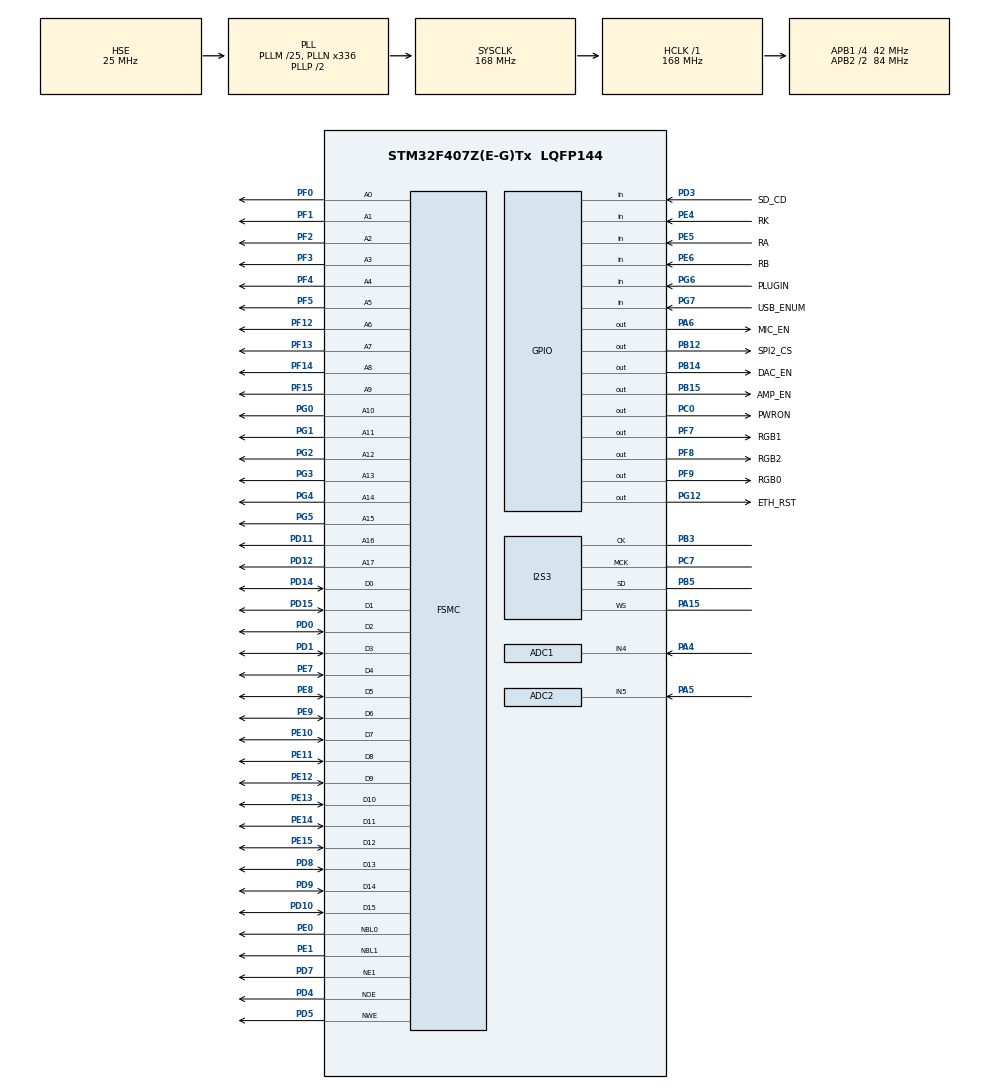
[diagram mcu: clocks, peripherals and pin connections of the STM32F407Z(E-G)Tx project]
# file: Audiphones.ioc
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ADC1.Channel-0\#ChannelRegularConversion=ADC_CHANNEL_4
ADC1.ClockPrescaler=ADC_CLOCK_SYNC_PCLK_DIV8
ADC1.ContinuousConvMode=DISABLE
ADC1.DMAContinuousRequests=DISABLE
ADC1.DataAlign=ADC_DATAALIGN_LEFT
ADC1.DiscontinuousConvMode=DISABLE
ADC1.EOCSelection=ADC_EOC_SINGLE_CONV
ADC1.EnableAnalogWatchDog=false
ADC1.ExternalTrigConv=ADC_SOFTWARE_START
ADC1.ExternalTrigConvEdge=ADC_EXTERNALTRIGCONVEDGE_NONE
ADC1.InjNumberOfConversion=0
ADC1.NbrOfConversion=1
ADC1.NbrOfConversionFlag=1
ADC1.Rank-0\#ChannelRegularConversion=1
ADC1.Resolution=ADC_RESOLUTION_12B
ADC1.SamplingTime-0\#ChannelRegularConversion=ADC_SAMPLETIME_3CYCLES
ADC1.ScanConvMode=DISABLE
ADC1.master=1
ADC2.Channel-0\#ChannelRegularConversion=ADC_CHANNEL_5
ADC2.ClockPrescaler=ADC_CLOCK_SYNC_PCLK_DIV8
ADC2.NbrOfConversionFlag=1
ADC2.Rank-0\#ChannelRegularConversion=1
ADC2.SamplingTime-0\#ChannelRegularConversion=ADC_SAMPLETIME_3CYCLES
FSMC.AddressSetupTime1=6
FSMC.BusTurnAroundDuration1=6
FSMC.DataSetupTime1=9
FSMC.WriteOperation1=FSMC_WRITE_OPERATION_ENABLE
I2S3.AudioFreq=I2S_AUDIOFREQ_16K
I2S3.ErrorAudioFreq=1.9 %
I2S3.FullDuplexMode=I2S_FULLDUPLEXMODE_DISABLE
I2S3.Instance=SPI$Index
I2S3.RealAudioFreq=16.304 KHz
I2S3.VirtualMode=I2S_MODE_MASTER
Mcu.Family=STM32F4
Mcu.Name=STM32F407Z(E-G)Tx
Mcu.Package=LQFP144
NVIC.PriorityGroup=NVIC_PRIORITYGROUP_2
NVIC.TIM3_IRQn=true\:0\:0\:false\:false\:true\:true
PA0-WKUP.Mode=SYS_WakeUp0
PA0-WKUP.Signal=SYS_WKUP
PA13.Mode=Serial_Wire
PA13.Signal=SYS_JTMS-SWDIO
PA14.Mode=Serial_Wire
PA14.Signal=SYS_JTCK-SWCLK
PA15.Mode=Half_Duplex_Master
PA15.Signal=I2S3_WS
PA4.Signal=ADCx_IN4
PA5.Signal=ADCx_IN5
PA6.GPIO_Label=MIC_EN
PA6.Signal=GPIO_Output
PB12.GPIO_Label=SPI2_CS
PB12.PinState=GPIO_PIN_SET
PB12.Signal=GPIO_Output
PB14.GPIO_Label=DAC_EN
PB14.Signal=GPIO_Output
PB15.GPIO_Label=AMP_EN
PB15.Signal=GPIO_Output
PB3.Mode=Half_Duplex_Master
PB3.Signal=I2S3_CK
PB5.Mode=Half_Duplex_Master
PB5.Signal=I2S3_SD
PC0.GPIO_Label=PWRON
PC0.Signal=GPIO_Output
PC14-OSC32_IN.Mode=LSE-External-Oscillator
PC14-OSC32_IN.Signal=RCC_OSC32_IN
PC15-OSC32_OUT.Mode=LSE-External-Oscillator
PC15-OSC32_OUT.Signal=RCC_OSC32_OUT
PC7.Mode=Master_Clock_Activated
PC7.Signal=I2S3_MCK
PD0.Signal=FSMC_D2_DA2
PD1.Signal=FSMC_D3_DA3
PD10.Signal=FSMC_D15_DA15
PD11.Signal=FSMC_A16_CLE
PD12.Signal=FSMC_A17_ALE
PD14.Signal=FSMC_D0_DA0
PD15.Signal=FSMC_D1_DA1
PD3.GPIO_Label=SD_CD
PD3.Signal=GPIO_Input
PD4.Signal=FSMC_NOE
PD5.Signal=FSMC_NWE
PD7.Mode=NorPsramChipSelect1_1
PD7.Signal=FSMC_NE1
PD8.Signal=FSMC_D13_DA13
PD9.Signal=FSMC_D14_DA14
PE0.Signal=FSMC_NBL0
PE1.Signal=FSMC_NBL1
PE10.Signal=FSMC_D7_DA7
PE11.Signal=FSMC_D8_DA8
PE12.Signal=FSMC_D9_DA9
PE13.Signal=FSMC_D10_DA10
PE14.Signal=FSMC_D11_DA11
PE15.Signal=FSMC_D12_DA12
PE4.GPIO_Label=RK
PE4.Signal=GPIO_Input
PE5.GPIO_Label=RA
PE5.Signal=GPIO_Input
PE6.GPIO_Label=RB
PE6.Signal=GPIO_Input
PE7.Signal=FSMC_D4_DA4
PE8.Signal=FSMC_D5_DA5
PE9.Signal=FSMC_D6_DA6
PF0.Signal=FSMC_A0
PF1.Signal=FSMC_A1
PF12.Signal=FSMC_A6
PF13.Signal=FSMC_A7
PF14.Signal=FSMC_A8
PF15.Signal=FSMC_A9
PF2.Signal=FSMC_A2
PF3.Signal=FSMC_A3
PF4.Signal=FSMC_A4
PF5.Signal=FSMC_A5
PF7.GPIO_Label=RGB1
PF7.Signal=GPIO_Output
PF8.GPIO_Label=RGB2
PF8.Signal=GPIO_Output
PF9.GPIO_Label=RGB0
PF9.Signal=GPIO_Output
PG0.Signal=FSMC_A10
PG1.Signal=FSMC_A11
PG12.GPIO_Label=ETH_RST
PG12.PinState=GPIO_PIN_SET
PG12.Signal=GPIO_Output
PG2.Signal=FSMC_A12
PG3.Signal=FSMC_A13
PG4.Signal=FSMC_A14
PG5.Signal=FSMC_A15
PG6.GPIO_Label=PLUGIN
PG6.Signal=GPIO_Input
PG7.GPIO_Label=USB_ENUM
PG7.Signal=GPIO_Input
PH0-OSC_IN.Mode=HSE-External-Oscillator
PH0-OSC_IN.Signal=RCC_OSC_IN
PH1-OSC_OUT.Mode=HSE-External-Oscillator
PH1-OSC_OUT.Signal=RCC_OSC_OUT
ProjectManager.HeapSize=0x800
ProjectManager.StackSize=0x400
ProjectManager.TargetToolchain=MDK-ARM V5
RCC.48MHZClocksFreq_Value=48000000
RCC.AHBFreq_Value=168000000
RCC.APB1CLKDivider=RCC_HCLK_DIV4
RCC.APB1Freq_Value=42000000
RCC.APB1TimFreq_Value=84000000
RCC.APB2CLKDivider=RCC_HCLK_DIV2
RCC.APB2Freq_Value=84000000
RCC.APB2TimFreq_Value=168000000
RCC.CortexFreq_Value=21000000
RCC.Cortex_Div=SYSTICK_CLKSOURCE_HCLK_DIV8
RCC.EnbaleCSS=true
RCC.HCLKFreq_Value=168000000
RCC.HSE_VALUE=25000000
RCC.HSI_VALUE=16000000
RCC.PLLM=25
RCC.PLLN=336
RCC.PLLQ=7
RCC.PLLSourceVirtual=RCC_PLLSOURCE_HSE
RCC.RCC_RTC_Clock_SourceVirtual=RCC_RTCCLKSOURCE_LSE
RCC.SYSCLKFreq_VALUE=168000000
RCC.SYSCLKSource=RCC_SYSCLKSOURCE_PLLCLK
RCC.VCOOutputFreq_Value=336000000
SH.ADCx_IN4.0=ADC1_IN4,IN4
SH.ADCx_IN5.0=ADC2_IN5,IN5
SH.FSMC_A0.0=FSMC_A0,18b-a1
SH.FSMC_A1.0=FSMC_A1,18b-a1
SH.FSMC_A10.0=FSMC_A10,18b-a1
SH.FSMC_A11.0=FSMC_A11,18b-a1
SH.FSMC_A12.0=FSMC_A12,18b-a1
SH.FSMC_A13.0=FSMC_A13,18b-a1
SH.FSMC_A14.0=FSMC_A14,18b-a1
SH.FSMC_A15.0=FSMC_A15,18b-a1
SH.FSMC_A16_CLE.0=FSMC_A16,18b-a1
SH.FSMC_A17_ALE.0=FSMC_A17,18b-a1
SH.FSMC_A2.0=FSMC_A2,18b-a1
SH.FSMC_A3.0=FSMC_A3,18b-a1
SH.FSMC_A4.0=FSMC_A4,18b-a1
SH.FSMC_A5.0=FSMC_A5,18b-a1
SH.FSMC_A6.0=FSMC_A6,18b-a1
SH.FSMC_A7.0=FSMC_A7,18b-a1
SH.FSMC_A8.0=FSMC_A8,18b-a1
SH.FSMC_A9.0=FSMC_A9,18b-a1
SH.FSMC_D0_DA0.0=FSMC_D0,16b-d1
SH.FSMC_D10_DA10.0=FSMC_D10,16b-d1
SH.FSMC_D11_DA11.0=FSMC_D11,16b-d1
SH.FSMC_D12_DA12.0=FSMC_D12,16b-d1
SH.FSMC_D13_DA13.0=FSMC_D13,16b-d1
SH.FSMC_D14_DA14.0=FSMC_D14,16b-d1
SH.FSMC_D15_DA15.0=FSMC_D15,16b-d1
SH.FSMC_D1_DA1.0=FSMC_D1,16b-d1
SH.FSMC_D2_DA2.0=FSMC_D2,16b-d1
SH.FSMC_D3_DA3.0=FSMC_D3,16b-d1
SH.FSMC_D4_DA4.0=FSMC_D4,16b-d1
SH.FSMC_D5_DA5.0=FSMC_D5,16b-d1
SH.FSMC_D6_DA6.0=FSMC_D6,16b-d1
SH.FSMC_D7_DA7.0=FSMC_D7,16b-d1
SH.FSMC_D8_DA8.0=FSMC_D8,16b-d1
SH.FSMC_D9_DA9.0=FSMC_D9,16b-d1
SH.FSMC_NBL0.0=FSMC_NBL0,2ByteEnable1
SH.FSMC_NBL1.0=FSMC_NBL1,2ByteEnable1
SH.FSMC_NOE.0=FSMC_NOE,Sram1
SH.FSMC_NWE.0=FSMC_NWE,Sram1
TIM3.ClockDivision=TIM_CLOCKDIVISION_DIV2
TIM3.Period=2625-1
VP_TIM3_VS_ClockSourceINT.Mode=Internal
board=Audiphones

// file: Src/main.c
/**
  ******************************************************************************
  * File Name          : main.c
  * Description        : Main program body
  ******************************************************************************
  ** This notice applies to any and all portions of this file
  * that are not between comment pairs USER CODE BEGIN and
  * USER CODE END. Other portions of this file, whether
  * inserted by the user or by software development tools
  * are owned by their respective copyright owners.
  *
  * COPYRIGHT(c) 2017 STMicroelectronics
  *
  * Redistribution and use in source and binary forms, with or without modification,
  * are permitted provided that the following conditions are met:
  *   1. Redistributions of source code must retain the above copyright notice,
  *      this list of conditions and the following disclaimer.
  *   2. Redistributions in binary form must reproduce the above copyright notice,
  *      this list of conditions and the following disclaimer in the documentation
  *      and/or other materials provided with the distribution.
  *   3. Neither the name of STMicroelectronics nor the names of its contributors
  *      may be used to endorse or promote products derived from this software
  *      without specific prior written permission.
  *
  * THIS SOFTWARE IS PROVIDED BY THE COPYRIGHT HOLDERS AND CONTRIBUTORS "AS IS"
  * AND ANY EXPRESS OR IMPLIED WARRANTIES, INCLUDING, BUT NOT LIMITED TO, THE
  * IMPLIED WARRANTIES OF MERCHANTABILITY AND FITNESS FOR A PARTICULAR PURPOSE ARE
  * DISCLAIMED. IN NO EVENT SHALL THE COPYRIGHT HOLDER OR CONTRIBUTORS BE LIABLE
  * FOR ANY DIRECT, INDIRECT, INCIDENTAL, SPECIAL, EXEMPLARY, OR CONSEQUENTIAL
  * DAMAGES (INCLUDING, BUT NOT LIMITED TO, PROCUREMENT OF SUBSTITUTE GOODS OR
  * SERVICES; LOSS OF USE, DATA, OR PROFITS; OR BUSINESS INTERRUPTION) HOWEVER
  * CAUSED AND ON ANY THEORY OF LIABILITY, WHETHER IN CONTRACT, STRICT LIABILITY,
  * OR TORT (INCLUDING NEGLIGENCE OR OTHERWISE) ARISING IN ANY WAY OUT OF THE USE
  * OF THIS SOFTWARE, EVEN IF ADVISED OF THE POSSIBILITY OF SUCH DAMAGE.
  *
  ******************************************************************************
  */
#include "main.h"
#include "stm32f4xx_hal.h"

ADC_HandleTypeDef hadc1;
ADC_HandleTypeDef hadc2;

I2S_HandleTypeDef hi2s3;

TIM_HandleTypeDef htim3;

SRAM_HandleTypeDef hsram1;

/* USER CODE BEGIN PV */
/* Private variables ---------------------------------------------------------*/

/* USER CODE END PV */

void SystemClock_Config(void);
static void MX_GPIO_Init(void);
static void MX_FSMC_Init(void);
static void MX_ADC1_Init(void);
static void MX_ADC2_Init(void);
static void MX_TIM3_Init(void);
static void MX_I2S3_Init(void);

/* USER CODE BEGIN PFP */
/* Private function prototypes -----------------------------------------------*/

/* USER CODE END PFP */

int main(void)
{

  /* MCU Configuration----------------------------------------------------------*/

  /* Reset of all peripherals, Initializes the Flash interface and the Systick. */
  HAL_Init();

  /* Configure the system clock */
  SystemClock_Config();

  /* Initialize all configured peripherals */
  MX_GPIO_Init();
  MX_FSMC_Init();
  MX_ADC1_Init();
  MX_ADC2_Init();
  MX_TIM3_Init();
  MX_I2S3_Init();

  /* Infinite loop */
  /* USER CODE BEGIN WHILE */
  HAL_GPIO_WritePin(DAC_EN_GPIO_Port,DAC_EN_Pin,GPIO_PIN_SET);
  HAL_GPIO_WritePin(AMP_EN_GPIO_Port,AMP_EN_Pin,GPIO_PIN_SET);
  HAL_GPIO_WritePin(MIC_EN_GPIO_Port,MIC_EN_Pin,GPIO_PIN_SET);
   HAL_TIM_Base_Start_IT(&htim3);
  while (1)
  {
  /* USER CODE END WHILE */

  }

}

/** System Clock Configuration
*/
void SystemClock_Config(void)
{

  RCC_OscInitTypeDef RCC_OscInitStruct;
  RCC_ClkInitTypeDef RCC_ClkInitStruct;
  RCC_PeriphCLKInitTypeDef PeriphClkInitStruct;

    /**Configure the main internal regulator output voltage
    */
  __HAL_RCC_PWR_CLK_ENABLE();

  __HAL_PWR_VOLTAGESCALING_CONFIG(PWR_REGULATOR_VOLTAGE_SCALE1);

    /**Initializes the CPU, AHB and APB busses clocks
    */
  RCC_OscInitStruct.OscillatorType = RCC_OSCILLATORTYPE_HSE;
  RCC_OscInitStruct.HSEState = RCC_HSE_ON;
  RCC_OscInitStruct.PLL.PLLState = RCC_PLL_ON;
  RCC_OscInitStruct.PLL.PLLSource = RCC_PLLSOURCE_HSE;
  RCC_OscInitStruct.PLL.PLLM = 25;
  RCC_OscInitStruct.PLL.PLLN = 336;
  RCC_OscInitStruct.PLL.PLLP = RCC_PLLP_DIV2;
  RCC_OscInitStruct.PLL.PLLQ = 7;
  if (HAL_RCC_OscConfig(&RCC_OscInitStruct) != HAL_OK)
  {
    _Error_Handler(__FILE__, __LINE__);
  }

    /**Initializes the CPU, AHB and APB busses clocks
    */
  RCC_ClkInitStruct.ClockType = RCC_CLOCKTYPE_HCLK|RCC_CLOCKTYPE_SYSCLK
                              |RCC_CLOCKTYPE_PCLK1|RCC_CLOCKTYPE_PCLK2;
  RCC_ClkInitStruct.SYSCLKSource = RCC_SYSCLKSOURCE_PLLCLK;
  RCC_ClkInitStruct.AHBCLKDivider = RCC_SYSCLK_DIV1;
  RCC_ClkInitStruct.APB1CLKDivider = RCC_HCLK_DIV4;
  RCC_ClkInitStruct.APB2CLKDivider = RCC_HCLK_DIV2;

  if (HAL_RCC_ClockConfig(&RCC_ClkInitStruct, FLASH_LATENCY_5) != HAL_OK)
  {
    _Error_Handler(__FILE__, __LINE__);
  }

  PeriphClkInitStruct.PeriphClockSelection = RCC_PERIPHCLK_I2S;
  PeriphClkInitStruct.PLLI2S.PLLI2SN = 192;
  PeriphClkInitStruct.PLLI2S.PLLI2SR = 2;
  if (HAL_RCCEx_PeriphCLKConfig(&PeriphClkInitStruct) != HAL_OK)
  {
    _Error_Handler(__FILE__, __LINE__);
  }

    /**Enables the Clock Security System
    */
  HAL_RCC_EnableCSS();

    /**Configure the Systick interrupt time
    */
  HAL_SYSTICK_Config(HAL_RCC_GetHCLKFreq()/8000);

    /**Configure the Systick
    */
  HAL_SYSTICK_CLKSourceConfig(SYSTICK_CLKSOURCE_HCLK_DIV8);

  /* SysTick_IRQn interrupt configuration */
  HAL_NVIC_SetPriority(SysTick_IRQn, 0, 0);
}

/* ADC1 init function */
static void MX_ADC1_Init(void)
{

  ADC_ChannelConfTypeDef sConfig;

    /**Configure the global features of the ADC (Clock, Resolution, Data Alignment and number of conversion)
    */
  hadc1.Instance = ADC1;
  hadc1.Init.ClockPrescaler = ADC_CLOCK_SYNC_PCLK_DIV8;
  hadc1.Init.Resolution = ADC_RESOLUTION_12B;
  hadc1.Init.ScanConvMode = DISABLE;
  hadc1.Init.ContinuousConvMode = DISABLE;
  hadc1.Init.DiscontinuousConvMode = DISABLE;
  hadc1.Init.ExternalTrigConvEdge = ADC_EXTERNALTRIGCONVEDGE_NONE;
  hadc1.Init.ExternalTrigConv = ADC_SOFTWARE_START;
  hadc1.Init.DataAlign = ADC_DATAALIGN_LEFT;
  hadc1.Init.NbrOfConversion = 1;
  hadc1.Init.DMAContinuousRequests = DISABLE;
  hadc1.Init.EOCSelection = ADC_EOC_SINGLE_CONV;
  if (HAL_ADC_Init(&hadc1) != HAL_OK)
  {
    _Error_Handler(__FILE__, __LINE__);
  }

    /**Configure for the selected ADC regular channel its corresponding rank in the sequencer and its sample time.
    */
  sConfig.Channel = ADC_CHANNEL_4;
  sConfig.Rank = 1;
  sConfig.SamplingTime = ADC_SAMPLETIME_3CYCLES;
  if (HAL_ADC_ConfigChannel(&hadc1, &sConfig) != HAL_OK)
  {
    _Error_Handler(__FILE__, __LINE__);
  }

}

/* ADC2 init function */
static void MX_ADC2_Init(void)
{

  ADC_ChannelConfTypeDef sConfig;

    /**Configure the global features of the ADC (Clock, Resolution, Data Alignment and number of conversion)
    */
  hadc2.Instance = ADC2;
  hadc2.Init.ClockPrescaler = ADC_CLOCK_SYNC_PCLK_DIV8;
  hadc2.Init.Resolution = ADC_RESOLUTION_12B;
  hadc2.Init.ScanConvMode = DISABLE;
  hadc2.Init.ContinuousConvMode = DISABLE;
  hadc2.Init.DiscontinuousConvMode = DISABLE;
  hadc2.Init.ExternalTrigConvEdge = ADC_EXTERNALTRIGCONVEDGE_NONE;
  hadc2.Init.ExternalTrigConv = ADC_SOFTWARE_START;
  hadc2.Init.DataAlign = ADC_DATAALIGN_RIGHT;
  hadc2.Init.NbrOfConversion = 1;
  hadc2.Init.DMAContinuousRequests = DISABLE;
  hadc2.Init.EOCSelection = ADC_EOC_SINGLE_CONV;
  if (HAL_ADC_Init(&hadc2) != HAL_OK)
  {
    _Error_Handler(__FILE__, __LINE__);
  }

    /**Configure for the selected ADC regular channel its corresponding rank in the sequencer and its sample time.
    */
  sConfig.Channel = ADC_CHANNEL_5;
  sConfig.Rank = 1;
  sConfig.SamplingTime = ADC_SAMPLETIME_3CYCLES;
  if (HAL_ADC_ConfigChannel(&hadc2, &sConfig) != HAL_OK)
  {
    _Error_Handler(__FILE__, __LINE__);
  }

}

/* I2S3 init function */
static void MX_I2S3_Init(void)
{

  hi2s3.Instance = SPI3;
  hi2s3.Init.Mode = I2S_MODE_MASTER_TX;
  hi2s3.Init.Standard = I2S_STANDARD_PHILIPS;
  hi2s3.Init.DataFormat = I2S_DATAFORMAT_16B;
  hi2s3.Init.MCLKOutput = I2S_MCLKOUTPUT_ENABLE;
  hi2s3.Init.AudioFreq = I2S_AUDIOFREQ_16K;
  hi2s3.Init.CPOL = I2S_CPOL_LOW;
  hi2s3.Init.ClockSource = I2S_CLOCK_PLL;
  hi2s3.Init.FullDuplexMode = I2S_FULLDUPLEXMODE_DISABLE;
  if (HAL_I2S_Init(&hi2s3) != HAL_OK)
  {
    _Error_Handler(__FILE__, __LINE__);
  }

}

/* TIM3 init function */
static void MX_TIM3_Init(void)
{

  TIM_ClockConfigTypeDef sClockSourceConfig;
  TIM_MasterConfigTypeDef sMasterConfig;

  htim3.Instance = TIM3;
  htim3.Init.Prescaler = 0;
  htim3.Init.CounterMode = TIM_COUNTERMODE_UP;
  htim3.Init.Period = 2625-1;
  htim3.Init.ClockDivision = TIM_CLOCKDIVISION_DIV2;
  if (HAL_TIM_Base_Init(&htim3) != HAL_OK)
  {
    _Error_Handler(__FILE__, __LINE__);
  }

  sClockSourceConfig.ClockSource = TIM_CLOCKSOURCE_INTERNAL;
  if (HAL_TIM_ConfigClockSource(&htim3, &sClockSourceConfig) != HAL_OK)
  {
    _Error_Handler(__FILE__, __LINE__);
  }

  sMasterConfig.MasterOutputTrigger = TIM_TRGO_RESET;
  sMasterConfig.MasterSlaveMode = TIM_MASTERSLAVEMODE_DISABLE;
  if (HAL_TIMEx_MasterConfigSynchronization(&htim3, &sMasterConfig) != HAL_OK)
  {
    _Error_Handler(__FILE__, __LINE__);
  }

}

/** Configure pins as
        * Analog
        * Input
        * Output
        * EVENT_OUT
        * EXTI
        * Free pins are configured automatically as Analog (this feature is enabled through
        * the Code Generation settings)
*/
static void MX_GPIO_Init(void)
{

  GPIO_InitTypeDef GPIO_InitStruct;

  /* GPIO Ports Clock Enable */
  __HAL_RCC_GPIOE_CLK_ENABLE();
  __HAL_RCC_GPIOC_CLK_ENABLE();
  __HAL_RCC_GPIOF_CLK_ENABLE();
  __HAL_RCC_GPIOH_CLK_ENABLE();
  __HAL_RCC_GPIOA_CLK_ENABLE();
  __HAL_RCC_GPIOB_CLK_ENABLE();
  __HAL_RCC_GPIOG_CLK_ENABLE();
  __HAL_RCC_GPIOD_CLK_ENABLE();

  /*Configure GPIO pin Output Level */
  HAL_GPIO_WritePin(GPIOF, RGB1_Pin|RGB2_Pin|RGB0_Pin, GPIO_PIN_RESET);

  /*Configure GPIO pin Output Level */
  HAL_GPIO_WritePin(PWRON_GPIO_Port, PWRON_Pin, GPIO_PIN_RESET);

  /*Configure GPIO pin Output Level */
  HAL_GPIO_WritePin(MIC_EN_GPIO_Port, MIC_EN_Pin, GPIO_PIN_RESET);

  /*Configure GPIO pin Output Level */
  HAL_GPIO_WritePin(SPI2_CS_GPIO_Port, SPI2_CS_Pin, GPIO_PIN_SET);

  /*Configure GPIO pin Output Level */
  HAL_GPIO_WritePin(GPIOB, DAC_EN_Pin|AMP_EN_Pin, GPIO_PIN_RESET);

  /*Configure GPIO pin Output Level */
  HAL_GPIO_WritePin(ETH_RST_GPIO_Port, ETH_RST_Pin, GPIO_PIN_SET);

  /*Configure GPIO pins : PE2 PE3 */
  GPIO_InitStruct.Pin = GPIO_PIN_2|GPIO_PIN_3;
  GPIO_InitStruct.Mode = GPIO_MODE_ANALOG;
  GPIO_InitStruct.Pull = GPIO_NOPULL;
  HAL_GPIO_Init(GPIOE, &GPIO_InitStruct);

  /*Configure GPIO pins : RK_Pin RA_Pin RB_Pin */
  GPIO_InitStruct.Pin = RK_Pin|RA_Pin|RB_Pin;
  GPIO_InitStruct.Mode = GPIO_MODE_INPUT;
  GPIO_InitStruct.Pull = GPIO_NOPULL;
  HAL_GPIO_Init(GPIOE, &GPIO_InitStruct);

  /*Configure GPIO pins : PC13 PC1 PC2 PC3
                           PC4 PC5 PC6 PC8
                           PC9 PC10 PC11 PC12 */
  GPIO_InitStruct.Pin = GPIO_PIN_13|GPIO_PIN_1|GPIO_PIN_2|GPIO_PIN_3
                          |GPIO_PIN_4|GPIO_PIN_5|GPIO_PIN_6|GPIO_PIN_8
                          |GPIO_PIN_9|GPIO_PIN_10|GPIO_PIN_11|GPIO_PIN_12;
  GPIO_InitStruct.Mode = GPIO_MODE_ANALOG;
  GPIO_InitStruct.Pull = GPIO_NOPULL;
  HAL_GPIO_Init(GPIOC, &GPIO_InitStruct);

  /*Configure GPIO pins : PF6 PF10 PF11 */
  GPIO_InitStruct.Pin = GPIO_PIN_6|GPIO_PIN_10|GPIO_PIN_11;
  GPIO_InitStruct.Mode = GPIO_MODE_ANALOG;
  GPIO_InitStruct.Pull = GPIO_NOPULL;
  HAL_GPIO_Init(GPIOF, &GPIO_InitStruct);

  /*Configure GPIO pins : RGB1_Pin RGB2_Pin RGB0_Pin */
  GPIO_InitStruct.Pin = RGB1_Pin|RGB2_Pin|RGB0_Pin;
  GPIO_InitStruct.Mode = GPIO_MODE_OUTPUT_PP;
  GPIO_InitStruct.Pull = GPIO_NOPULL;
  GPIO_InitStruct.Speed = GPIO_SPEED_FREQ_LOW;
  HAL_GPIO_Init(GPIOF, &GPIO_InitStruct);

  /*Configure GPIO pin : PWRON_Pin */
  GPIO_InitStruct.Pin = PWRON_Pin;
  GPIO_InitStruct.Mode = GPIO_MODE_OUTPUT_PP;
  GPIO_InitStruct.Pull = GPIO_NOPULL;
  GPIO_InitStruct.Speed = GPIO_SPEED_FREQ_LOW;
  HAL_GPIO_Init(PWRON_GPIO_Port, &GPIO_InitStruct);

  /*Configure GPIO pins : PA1 PA2 PA3 PA7
                           PA8 PA9 PA10 PA11
                           PA12 */
  GPIO_InitStruct.Pin = GPIO_PIN_1|GPIO_PIN_2|GPIO_PIN_3|GPIO_PIN_7
                          |GPIO_PIN_8|GPIO_PIN_9|GPIO_PIN_10|GPIO_PIN_11
                          |GPIO_PIN_12;
  GPIO_InitStruct.Mode = GPIO_MODE_ANALOG;
  GPIO_InitStruct.Pull = GPIO_NOPULL;
  HAL_GPIO_Init(GPIOA, &GPIO_InitStruct);

  /*Configure GPIO pin : MIC_EN_Pin */
  GPIO_InitStruct.Pin = MIC_EN_Pin;
  GPIO_InitStruct.Mode = GPIO_MODE_OUTPUT_PP;
  GPIO_InitStruct.Pull = GPIO_NOPULL;
  GPIO_InitStruct.Speed = GPIO_SPEED_FREQ_LOW;
  HAL_GPIO_Init(MIC_EN_GPIO_Port, &GPIO_InitStruct);

  /*Configure GPIO pins : PB0 PB1 PB2 PB10
                           PB11 PB13 PB4 PB6
                           PB7 PB8 PB9 */
  GPIO_InitStruct.Pin = GPIO_PIN_0|GPIO_PIN_1|GPIO_PIN_2|GPIO_PIN_10
                          |GPIO_PIN_11|GPIO_PIN_13|GPIO_PIN_4|GPIO_PIN_6
                          |GPIO_PIN_7|GPIO_PIN_8|GPIO_PIN_9;
  GPIO_InitStruct.Mode = GPIO_MODE_ANALOG;
  GPIO_InitStruct.Pull = GPIO_NOPULL;
  HAL_GPIO_Init(GPIOB, &GPIO_InitStruct);

  /*Configure GPIO pins : SPI2_CS_Pin DAC_EN_Pin AMP_EN_Pin */
  GPIO_InitStruct.Pin = SPI2_CS_Pin|DAC_EN_Pin|AMP_EN_Pin;
  GPIO_InitStruct.Mode = GPIO_MODE_OUTPUT_PP;
  GPIO_InitStruct.Pull = GPIO_NOPULL;
  GPIO_InitStruct.Speed = GPIO_SPEED_FREQ_LOW;
  HAL_GPIO_Init(GPIOB, &GPIO_InitStruct);

  /*Configure GPIO pins : PD13 PD2 PD6 */
  GPIO_InitStruct.Pin = GPIO_PIN_13|GPIO_PIN_2|GPIO_PIN_6;
  GPIO_InitStruct.Mode = GPIO_MODE_ANALOG;
  GPIO_InitStruct.Pull = GPIO_NOPULL;
  HAL_GPIO_Init(GPIOD, &GPIO_InitStruct);

  /*Configure GPIO pins : PLUGIN_Pin USB_ENUM_Pin */
  GPIO_InitStruct.Pin = PLUGIN_Pin|USB_ENUM_Pin;
  GPIO_InitStruct.Mode = GPIO_MODE_INPUT;
  GPIO_InitStruct.Pull = GPIO_NOPULL;
  HAL_GPIO_Init(GPIOG, &GPIO_InitStruct);

  /*Configure GPIO pins : PG8 PG9 PG10 PG11
                           PG13 PG14 PG15 */
  GPIO_InitStruct.Pin = GPIO_PIN_8|GPIO_PIN_9|GPIO_PIN_10|GPIO_PIN_11
                          |GPIO_PIN_13|GPIO_PIN_14|GPIO_PIN_15;
  GPIO_InitStruct.Mode = GPIO_MODE_ANALOG;
  GPIO_InitStruct.Pull = GPIO_NOPULL;
  HAL_GPIO_Init(GPIOG, &GPIO_InitStruct);

  /*Configure GPIO pin : SD_CD_Pin */
  GPIO_InitStruct.Pin = SD_CD_Pin;
  GPIO_InitStruct.Mode = GPIO_MODE_INPUT;
  GPIO_InitStruct.Pull = GPIO_NOPULL;
  HAL_GPIO_Init(SD_CD_GPIO_Port, &GPIO_InitStruct);

  /*Configure GPIO pin : ETH_RST_Pin */
  GPIO_InitStruct.Pin = ETH_RST_Pin;
  GPIO_InitStruct.Mode = GPIO_MODE_OUTPUT_PP;
  GPIO_InitStruct.Pull = GPIO_NOPULL;
  GPIO_InitStruct.Speed = GPIO_SPEED_FREQ_LOW;
  HAL_GPIO_Init(ETH_RST_GPIO_Port, &GPIO_InitStruct);

}

/* FSMC initialization function */
static void MX_FSMC_Init(void)
{
  FSMC_NORSRAM_TimingTypeDef Timing;

  /** Perform the SRAM1 memory initialization sequence
  */
  hsram1.Instance = FSMC_NORSRAM_DEVICE;
  hsram1.Extended = FSMC_NORSRAM_EXTENDED_DEVICE;
  /* hsram1.Init */
  hsram1.Init.NSBank = FSMC_NORSRAM_BANK1;
  hsram1.Init.DataAddressMux = FSMC_DATA_ADDRESS_MUX_DISABLE;
  hsram1.Init.MemoryType = FSMC_MEMORY_TYPE_SRAM;
  hsram1.Init.MemoryDataWidth = FSMC_NORSRAM_MEM_BUS_WIDTH_16;
  hsram1.Init.BurstAccessMode = FSMC_BURST_ACCESS_MODE_DISABLE;
  hsram1.Init.WaitSignalPolarity = FSMC_WAIT_SIGNAL_POLARITY_LOW;
  hsram1.Init.WrapMode = FSMC_WRAP_MODE_DISABLE;
  hsram1.Init.WaitSignalActive = FSMC_WAIT_TIMING_BEFORE_WS;
  hsram1.Init.WriteOperation = FSMC_WRITE_OPERATION_ENABLE;
  hsram1.Init.WaitSignal = FSMC_WAIT_SIGNAL_DISABLE;
  hsram1.Init.ExtendedMode = FSMC_EXTENDED_MODE_DISABLE;
  hsram1.Init.AsynchronousWait = FSMC_ASYNCHRONOUS_WAIT_DISABLE;
  hsram1.Init.WriteBurst = FSMC_WRITE_BURST_DISABLE;
  hsram1.Init.PageSize = FSMC_PAGE_SIZE_NONE;
  /* Timing */
  Timing.AddressSetupTime = 6;
  Timing.AddressHoldTime = 15;
  Timing.DataSetupTime = 9;
  Timing.BusTurnAroundDuration = 6;
  Timing.CLKDivision = 16;
  Timing.DataLatency = 17;
  Timing.AccessMode = FSMC_ACCESS_MODE_A;
  /* ExtTiming */

  if (HAL_SRAM_Init(&hsram1, &Timing, NULL) != HAL_OK)
  {
    _Error_Handler(__FILE__, __LINE__);
  }

}

void _Error_Handler(char * file, int line)
{
  while(1)
  {
  }
}

/************************ (C) COPYRIGHT STMicroelectronics *****END OF FILE****/
